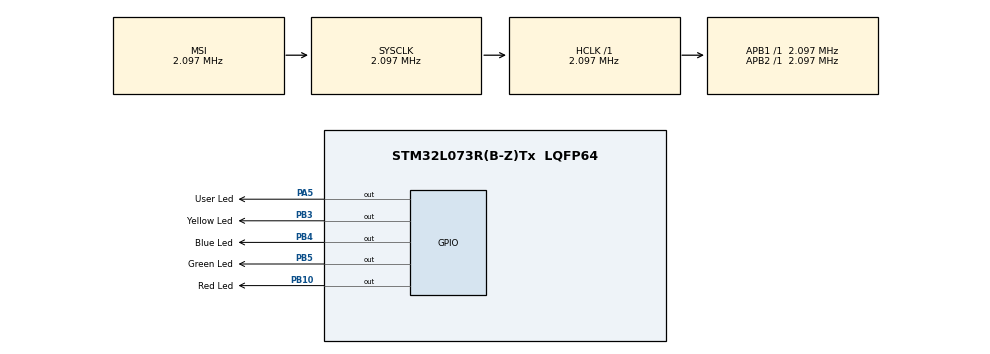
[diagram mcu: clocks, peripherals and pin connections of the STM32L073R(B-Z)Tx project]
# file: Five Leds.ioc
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Mcu.Family=STM32L0
Mcu.Name=STM32L073R(B-Z)Tx
Mcu.Package=LQFP64
PA5.GPIO_Label=User Led
PA5.Signal=GPIO_Output
PB10.GPIO_Label=Red Led
PB10.Signal=GPIO_Output
PB3.GPIO_Label=Yellow Led
PB3.Signal=GPIO_Output
PB4.GPIO_Label=Blue Led
PB4.Signal=GPIO_Output
PB5.GPIO_Label=Green Led
PB5.Signal=GPIO_Output
ProjectManager.HeapSize=0x200
ProjectManager.StackSize=0x400
ProjectManager.TargetToolchain=STM32CubeIDE
RCC.AHBFreq_Value=2097000
RCC.APB1Freq_Value=2097000
RCC.APB1TimFreq_Value=2097000
RCC.APB2Freq_Value=2097000
RCC.APB2TimFreq_Value=2097000
RCC.HSE_VALUE=8000000
RCC.HSI16_VALUE=16000000
RCC.HSI48_VALUE=48000000
RCC.HSI_VALUE=16000000
RCC.MSI_VALUE=2097000
RCC.SYSCLKFreq_VALUE=2097000
RCC.VCOOutputFreq_Value=48000000
board=NUCLEO-L073RZ

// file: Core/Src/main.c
/* USER CODE BEGIN Header */
/**
  ******************************************************************************
  * @file           : main.c
  * @brief          : Main program body
  ******************************************************************************
  * @attention
  *
  * Copyright (c) 2022 STMicroelectronics.
  * All rights reserved.
  *
  * This software is licensed under terms that can be found in the LICENSE file
  * in the root directory of this software component.
  * If no LICENSE file comes with this software, it is provided AS-IS.
  *
  ******************************************************************************
  */
/* USER CODE END Header */
#include "main.h"

void SystemClock_Config(void);
static void MX_GPIO_Init(void);
/* USER CODE BEGIN PFP */
void Blink_Five_Leds(void);
/* USER CODE END PFP */

int main(void)
{

  /* MCU Configuration--------------------------------------------------------*/

  /* Reset of all peripherals, Initializes the Flash interface and the Systick. */
  HAL_Init();

  /* Configure the system clock */
  SystemClock_Config();

  /* Initialize all configured peripherals */
  MX_GPIO_Init();

  /* Infinite loop */
  while (1)
  {
     Blink_Five_Leds();
  }
}

void SystemClock_Config(void)
{
  RCC_OscInitTypeDef RCC_OscInitStruct = {0};
  RCC_ClkInitTypeDef RCC_ClkInitStruct = {0};

  /** Configure the main internal regulator output voltage
  */
  __HAL_PWR_VOLTAGESCALING_CONFIG(PWR_REGULATOR_VOLTAGE_SCALE1);

  /** Initializes the RCC Oscillators according to the specified parameters
  * in the RCC_OscInitTypeDef structure.
  */
  RCC_OscInitStruct.OscillatorType = RCC_OSCILLATORTYPE_MSI;
  RCC_OscInitStruct.MSIState = RCC_MSI_ON;
  RCC_OscInitStruct.MSICalibrationValue = 0;
  RCC_OscInitStruct.MSIClockRange = RCC_MSIRANGE_5;
  RCC_OscInitStruct.PLL.PLLState = RCC_PLL_NONE;
  if (HAL_RCC_OscConfig(&RCC_OscInitStruct) != HAL_OK)
  {
    Error_Handler();
  }

  /** Initializes the CPU, AHB and APB buses clocks
  */
  RCC_ClkInitStruct.ClockType = RCC_CLOCKTYPE_HCLK|RCC_CLOCKTYPE_SYSCLK
                              |RCC_CLOCKTYPE_PCLK1|RCC_CLOCKTYPE_PCLK2;
  RCC_ClkInitStruct.SYSCLKSource = RCC_SYSCLKSOURCE_MSI;
  RCC_ClkInitStruct.AHBCLKDivider = RCC_SYSCLK_DIV1;
  RCC_ClkInitStruct.APB1CLKDivider = RCC_HCLK_DIV1;
  RCC_ClkInitStruct.APB2CLKDivider = RCC_HCLK_DIV1;

  if (HAL_RCC_ClockConfig(&RCC_ClkInitStruct, FLASH_LATENCY_0) != HAL_OK)
  {
    Error_Handler();
  }
}

static void MX_GPIO_Init(void)
{
  GPIO_InitTypeDef GPIO_InitStruct = {0};

  /* GPIO Ports Clock Enable */
  __HAL_RCC_GPIOA_CLK_ENABLE();
  __HAL_RCC_GPIOB_CLK_ENABLE();

  /*Configure GPIO pin Output Level */
  HAL_GPIO_WritePin(User_Led_GPIO_Port, User_Led_Pin, GPIO_PIN_RESET);

  /*Configure GPIO pin Output Level */
  HAL_GPIO_WritePin(GPIOB, Red_Led_Pin|Yellow_Led_Pin|Blue_Led_Pin|Green_Led_Pin, GPIO_PIN_RESET);

  /*Configure GPIO pin : User_Led_Pin */
  GPIO_InitStruct.Pin = User_Led_Pin;
  GPIO_InitStruct.Mode = GPIO_MODE_OUTPUT_PP;
  GPIO_InitStruct.Pull = GPIO_NOPULL;
  GPIO_InitStruct.Speed = GPIO_SPEED_FREQ_LOW;
  HAL_GPIO_Init(User_Led_GPIO_Port, &GPIO_InitStruct);

  /*Configure GPIO pins : Red_Led_Pin Yellow_Led_Pin Blue_Led_Pin Green_Led_Pin */
  GPIO_InitStruct.Pin = Red_Led_Pin|Yellow_Led_Pin|Blue_Led_Pin|Green_Led_Pin;
  GPIO_InitStruct.Mode = GPIO_MODE_OUTPUT_PP;
  GPIO_InitStruct.Pull = GPIO_NOPULL;
  GPIO_InitStruct.Speed = GPIO_SPEED_FREQ_LOW;
  HAL_GPIO_Init(GPIOB, &GPIO_InitStruct);

}

/* USER CODE BEGIN 4 */
void Blink_Five_Leds(void)
{
	HAL_GPIO_TogglePin(User_Led_GPIO_Port, User_Led_Pin);
	HAL_Delay(500);
	HAL_GPIO_TogglePin(GPIOB, Red_Led_Pin);
	HAL_Delay(500);
	HAL_GPIO_TogglePin(GPIOB, Green_Led_Pin);
	HAL_Delay(500);
	HAL_GPIO_TogglePin(GPIOB, Blue_Led_Pin);
	HAL_Delay(500);
	HAL_GPIO_TogglePin(GPIOB, Yellow_Led_Pin);
	HAL_Delay(500);
}
/* USER CODE END 4 */

void Error_Handler(void)
{
  __disable_irq();
  while (1)
  {
  }
}
